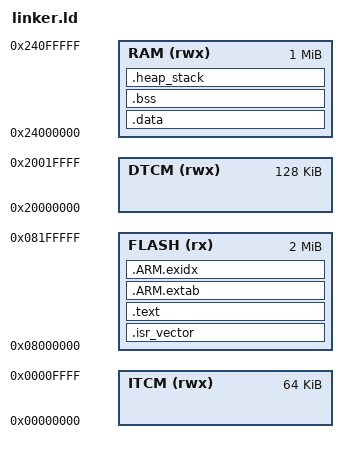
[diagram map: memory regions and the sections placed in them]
/*
 * Minimal linker script for STM32H743VI (2 MB flash, 1 MB RAM).
 * Author: jayis1
 * Copyright (c) 2026 jayis1 — MIT License
 */

ENTRY(Reset_Handler)

MEMORY
{
    FLASH (rx)  : ORIGIN = 0x08000000, LENGTH = 2048K
    RAM   (rwx) : ORIGIN = 0x24000000, LENGTH = 1024K
    ITCM  (rwx) : ORIGIN = 0x00000000, LENGTH = 64K
    DTCM  (rwx) : ORIGIN = 0x20000000, LENGTH = 128K
}

_estack = ORIGIN(RAM) + LENGTH(RAM);

SECTIONS
{
    .isr_vector :
    {
        . = ALIGN(4);
        KEEP(*(.isr_vector))
        . = ALIGN(4);
    } > FLASH

    .text :
    {
        . = ALIGN(4);
        *(.text)
        *(.text*)
        *(.rodata)
        *(.rodata*)
        . = ALIGN(4);
        _etext = .;
    } > FLASH

    .ARM.extab :
    {
        *(.ARM.extab* .gnu.linkonce.armextab.*)
    } > FLASH

    .ARM.exidx :
    {
        __exidx_start = .;
        *(.ARM.exidx* .gnu.linkonce.armexidx.*)
        __exidx_end = .;
    } > FLASH

    .data : AT (_etext)
    {
        . = ALIGN(4);
        _sdata = .;
        *(.data)
        *(.data*)
        . = ALIGN(4);
        _edata = .;
    } > RAM

    .bss :
    {
        . = ALIGN(4);
        _sbss = .;
        *(.bss)
        *(.bss*)
        *(COMMON)
        . = ALIGN(4);
        _ebss = .;
    } > RAM

    .heap_stack :
    {
        . = ALIGN(8);
        _end = .;
        . = . + 0x400;
        . = ALIGN(8);
    } > RAM
}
